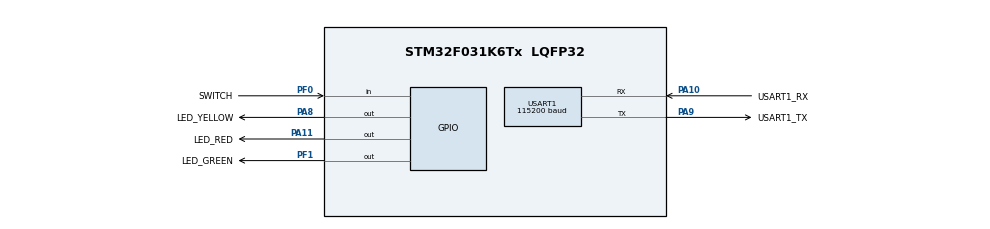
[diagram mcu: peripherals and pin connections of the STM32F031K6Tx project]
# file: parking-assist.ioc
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Mcu.Family=STM32F0
Mcu.Name=STM32F031K6Tx
Mcu.Package=LQFP32
PA10.GPIO_Label=USART1_RX
PA10.Mode=Asynchronous
PA10.Signal=USART1_RX
PA11.GPIO_Label=LED_RED
PA11.GPIO_ModeDefaultOutputPP=GPIO_MODE_OUTPUT_OD
PA11.GPIO_PuPd=GPIO_NOPULL
PA11.PinState=GPIO_PIN_SET
PA11.Signal=GPIO_Output
PA13.GPIO_Label=SWDIO
PA13.Mode=Serial_Wire
PA13.Signal=SYS_SWDIO
PA14.GPIO_Label=SWCLK
PA14.Mode=Serial_Wire
PA14.Signal=SYS_SWCLK
PA8.GPIO_Label=LED_YELLOW
PA8.GPIO_ModeDefaultOutputPP=GPIO_MODE_OUTPUT_OD
PA8.GPIO_PuPd=GPIO_NOPULL
PA8.PinState=GPIO_PIN_SET
PA8.Signal=GPIO_Output
PA9.GPIO_Label=USART1_TX
PA9.Mode=Asynchronous
PA9.Signal=USART1_TX
PF0-OSC_IN.GPIO_Label=SWITCH
PF0-OSC_IN.Signal=GPIO_Input
PF1-OSC_OUT.GPIO_Label=LED_GREEN
PF1-OSC_OUT.GPIO_ModeDefaultOutputPP=GPIO_MODE_OUTPUT_OD
PF1-OSC_OUT.GPIO_PuPd=GPIO_NOPULL
PF1-OSC_OUT.PinState=GPIO_PIN_SET
PF1-OSC_OUT.Signal=GPIO_Output
ProjectManager.HeapSize=0x200
ProjectManager.StackSize=0x400
ProjectManager.TargetToolchain=STM32CubeIDE
USART1.BaudRate=115200
USART1.VirtualMode-Asynchronous=VM_ASYNC
VP_RTC_VS_RTC_Activate.Mode=RTC_Enabled
board=NUCLEO-F031K6

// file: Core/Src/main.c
/* USER CODE BEGIN Header */
/**
  ******************************************************************************
  * @file           : main.c
  * @brief          : Main program body
  ******************************************************************************
  * @attention
  *
  * Copyright (c) 2022 STMicroelectronics.
  * All rights reserved.
  *
  * This software is licensed under terms that can be found in the LICENSE file
  * in the root directory of this software component.
  * If no LICENSE file comes with this software, it is provided AS-IS.
  *
  ******************************************************************************
  */
/* USER CODE END Header */
#include "main.h"

/* USER CODE BEGIN Includes */
#include "states.h"
/* USER CODE END Includes */

RTC_HandleTypeDef hrtc;

UART_HandleTypeDef huart1;

void SystemClock_Config(void);
static void MX_GPIO_Init(void);
static void MX_USART1_UART_Init(void);
static void MX_RTC_Init(void);

int main(void)
{

  /* MCU Configuration--------------------------------------------------------*/

  /* Reset of all peripherals, Initializes the Flash interface and the Systick. */
  HAL_Init();

  /* USER CODE BEGIN Init */
  system_init();
  /* USER CODE END Init */

  /* Configure the system clock */
  SystemClock_Config();

  /* Initialize all configured peripherals */
  MX_GPIO_Init();
  MX_USART1_UART_Init();
  MX_RTC_Init();

  /* Infinite loop */
  /* USER CODE BEGIN WHILE */
  while (1)
  {
	  system_loop();
    /* USER CODE END WHILE */

  }
}

void SystemClock_Config(void)
{
  RCC_OscInitTypeDef RCC_OscInitStruct = {0};
  RCC_ClkInitTypeDef RCC_ClkInitStruct = {0};
  RCC_PeriphCLKInitTypeDef PeriphClkInit = {0};

  /** Initializes the RCC Oscillators according to the specified parameters
  * in the RCC_OscInitTypeDef structure.
  */
  RCC_OscInitStruct.OscillatorType = RCC_OSCILLATORTYPE_HSI|RCC_OSCILLATORTYPE_LSI;
  RCC_OscInitStruct.HSIState = RCC_HSI_ON;
  RCC_OscInitStruct.HSICalibrationValue = RCC_HSICALIBRATION_DEFAULT;
  RCC_OscInitStruct.LSIState = RCC_LSI_ON;
  RCC_OscInitStruct.PLL.PLLState = RCC_PLL_NONE;
  if (HAL_RCC_OscConfig(&RCC_OscInitStruct) != HAL_OK)
  {
    Error_Handler();
  }
  /** Initializes the CPU, AHB and APB buses clocks
  */
  RCC_ClkInitStruct.ClockType = RCC_CLOCKTYPE_HCLK|RCC_CLOCKTYPE_SYSCLK
                              |RCC_CLOCKTYPE_PCLK1;
  RCC_ClkInitStruct.SYSCLKSource = RCC_SYSCLKSOURCE_HSI;
  RCC_ClkInitStruct.AHBCLKDivider = RCC_SYSCLK_DIV1;
  RCC_ClkInitStruct.APB1CLKDivider = RCC_HCLK_DIV1;

  if (HAL_RCC_ClockConfig(&RCC_ClkInitStruct, FLASH_LATENCY_0) != HAL_OK)
  {
    Error_Handler();
  }
  PeriphClkInit.PeriphClockSelection = RCC_PERIPHCLK_USART1|RCC_PERIPHCLK_RTC;
  PeriphClkInit.Usart1ClockSelection = RCC_USART1CLKSOURCE_PCLK1;
  PeriphClkInit.RTCClockSelection = RCC_RTCCLKSOURCE_LSI;
  if (HAL_RCCEx_PeriphCLKConfig(&PeriphClkInit) != HAL_OK)
  {
    Error_Handler();
  }
}

static void MX_RTC_Init(void)
{

  /** Initialize RTC Only
  */
  hrtc.Instance = RTC;
  hrtc.Init.HourFormat = RTC_HOURFORMAT_24;
  hrtc.Init.AsynchPrediv = 127;
  hrtc.Init.SynchPrediv = 255;
  hrtc.Init.OutPut = RTC_OUTPUT_DISABLE;
  hrtc.Init.OutPutPolarity = RTC_OUTPUT_POLARITY_HIGH;
  hrtc.Init.OutPutType = RTC_OUTPUT_TYPE_OPENDRAIN;
  if (HAL_RTC_Init(&hrtc) != HAL_OK)
  {
    Error_Handler();
  }

}

static void MX_USART1_UART_Init(void)
{

  huart1.Instance = USART1;
  huart1.Init.BaudRate = 115200;
  huart1.Init.WordLength = UART_WORDLENGTH_8B;
  huart1.Init.StopBits = UART_STOPBITS_1;
  huart1.Init.Parity = UART_PARITY_NONE;
  huart1.Init.Mode = UART_MODE_TX_RX;
  huart1.Init.HwFlowCtl = UART_HWCONTROL_NONE;
  huart1.Init.OverSampling = UART_OVERSAMPLING_16;
  huart1.Init.OneBitSampling = UART_ONE_BIT_SAMPLE_DISABLE;
  huart1.AdvancedInit.AdvFeatureInit = UART_ADVFEATURE_NO_INIT;
  if (HAL_UART_Init(&huart1) != HAL_OK)
  {
    Error_Handler();
  }

}

static void MX_GPIO_Init(void)
{
  GPIO_InitTypeDef GPIO_InitStruct = {0};

  /* GPIO Ports Clock Enable */
  __HAL_RCC_GPIOF_CLK_ENABLE();
  __HAL_RCC_GPIOA_CLK_ENABLE();

  /*Configure GPIO pin Output Level */
  HAL_GPIO_WritePin(LED_GREEN_GPIO_Port, LED_GREEN_Pin, GPIO_PIN_SET);

  /*Configure GPIO pin Output Level */
  HAL_GPIO_WritePin(GPIOA, LED_YELLOW_Pin|LED_RED_Pin, GPIO_PIN_SET);

  /*Configure GPIO pin : SWITCH_Pin */
  GPIO_InitStruct.Pin = SWITCH_Pin;
  GPIO_InitStruct.Mode = GPIO_MODE_INPUT;
  GPIO_InitStruct.Pull = GPIO_NOPULL;
  HAL_GPIO_Init(SWITCH_GPIO_Port, &GPIO_InitStruct);

  /*Configure GPIO pin : LED_GREEN_Pin */
  GPIO_InitStruct.Pin = LED_GREEN_Pin;
  GPIO_InitStruct.Mode = GPIO_MODE_OUTPUT_OD;
  GPIO_InitStruct.Pull = GPIO_NOPULL;
  GPIO_InitStruct.Speed = GPIO_SPEED_FREQ_LOW;
  HAL_GPIO_Init(LED_GREEN_GPIO_Port, &GPIO_InitStruct);

  /*Configure GPIO pins : LED_YELLOW_Pin LED_RED_Pin */
  GPIO_InitStruct.Pin = LED_YELLOW_Pin|LED_RED_Pin;
  GPIO_InitStruct.Mode = GPIO_MODE_OUTPUT_OD;
  GPIO_InitStruct.Pull = GPIO_NOPULL;
  GPIO_InitStruct.Speed = GPIO_SPEED_FREQ_LOW;
  HAL_GPIO_Init(GPIOA, &GPIO_InitStruct);

}

void Error_Handler(void)
{
  __disable_irq();
  while (1)
  {
  }
}
